AUTOSAR XML (schema 4-2-1)
package /ComponentTypes
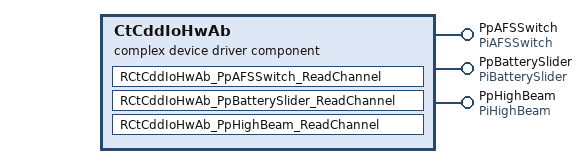
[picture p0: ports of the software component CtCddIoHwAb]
  complex device driver sw component type CtCddIoHwAb
    provide port PpAFSSwitch: server-com-spec{operation=ReadChannel, queue-length=1}, provided-interface=PiAFSSwitch
    provide port PpBatterySlider: server-com-spec{operation=ReadChannel, queue-length=1}, provided-interface=PiBatterySlider
    provide port PpHighBeam: server-com-spec{operation=ReadChannel, queue-length=1}, provided-interface=PiHighBeam
    behavior CtCddIoHwAb_InternalBehavior
      operation invoked event OIT_PpAFSSwitch_ReadChannel_PpAFSSwitch_ReadChannel: start-on-event=RCtCddIoHwAb_PpAFSSwitch_ReadChannel, operation=PpAFSSwitch.ReadChannel
      operation invoked event OIT_PpBatterySlider_ReadChannel_PpBatterySlider_ReadChannel: start-on-event=RCtCddIoHwAb_PpBatterySlider_ReadChannel, operation=PpBatterySlider.ReadChannel
      operation invoked event OIT_PiHighBeam_ReadChannel_PiHighBeam_ReadChannel: start-on-event=RCtCddIoHwAb_PpHighBeam_ReadChannel, operation=PpHighBeam.ReadChannel
      runnable RCtCddIoHwAb_PpAFSSwitch_ReadChannel
      runnable RCtCddIoHwAb_PpBatterySlider_ReadChannel
      runnable RCtCddIoHwAb_PpHighBeam_ReadChannel
  swc implementation CtCddIoHwAb_Implementation: behavior=CtCddIoHwAb_InternalBehavior
    code-descriptors:
      code Default: artifact-descriptors=autosar-engineering-object={short-label=Default, category=SWSRC}
